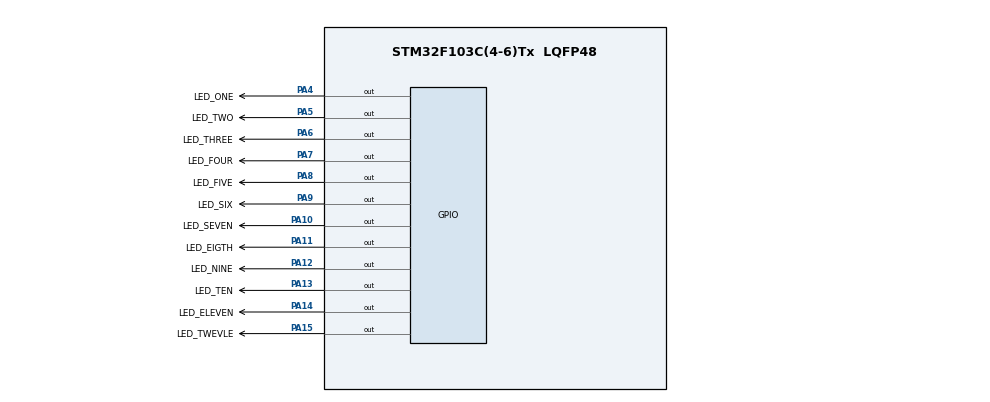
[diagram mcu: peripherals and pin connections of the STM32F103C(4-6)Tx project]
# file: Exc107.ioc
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Mcu.Family=STM32F1
Mcu.Name=STM32F103C(4-6)Tx
Mcu.Package=LQFP48
NVIC.PriorityGroup=NVIC_PRIORITYGROUP_4
PA10.GPIO_Label=LED_SEVEN
PA10.Signal=GPIO_Output
PA11.GPIO_Label=LED_EIGTH
PA11.Signal=GPIO_Output
PA12.GPIO_Label=LED_NINE
PA12.Signal=GPIO_Output
PA13.GPIO_Label=LED_TEN
PA13.Signal=GPIO_Output
PA14.GPIO_Label=LED_ELEVEN
PA14.Signal=GPIO_Output
PA15.GPIO_Label=LED_TWEVLE
PA15.Signal=GPIO_Output
PA4.GPIO_Label=LED_ONE
PA4.Signal=GPIO_Output
PA5.GPIO_Label=LED_TWO
PA5.Signal=GPIO_Output
PA6.GPIO_Label=LED_THREE
PA6.Signal=GPIO_Output
PA7.GPIO_Label=LED_FOUR
PA7.Signal=GPIO_Output
PA8.GPIO_Label=LED_FIVE
PA8.Signal=GPIO_Output
PA9.GPIO_Label=LED_SIX
PA9.Signal=GPIO_Output
ProjectManager.HeapSize=0x200
ProjectManager.StackSize=0x400
ProjectManager.TargetToolchain=STM32CubeIDE
RCC.APB1Freq_Value=8000000
RCC.APB2Freq_Value=8000000
board=custom

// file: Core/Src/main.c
/* USER CODE BEGIN Header */
/**
  ******************************************************************************
  * @file           : main.c
  * @brief          : Main program body
  ******************************************************************************
  * @attention
  *
  * Copyright (c) 2022 STMicroelectronics.
  * All rights reserved.
  *
  * This software is licensed under terms that can be found in the LICENSE file
  * in the root directory of this software component.
  * If no LICENSE file comes with this software, it is provided AS-IS.
  *
  ******************************************************************************
  */
/* USER CODE END Header */
#include "main.h"

void SystemClock_Config(void);
static void MX_GPIO_Init(void);

void clearAllClock(){
	//TODO
	HAL_GPIO_WritePin(LED_ONE_GPIO_Port, LED_ONE_Pin, SET);
	HAL_GPIO_WritePin(LED_TWO_GPIO_Port, LED_TWO_Pin, SET);
	HAL_GPIO_WritePin(LED_THREE_GPIO_Port, LED_THREE_Pin, SET);
	HAL_GPIO_WritePin(LED_FOUR_GPIO_Port, LED_FOUR_Pin, SET);
	HAL_GPIO_WritePin(LED_FIVE_GPIO_Port, LED_FIVE_Pin, SET);
	HAL_GPIO_WritePin(LED_SIX_GPIO_Port, LED_SIX_Pin, SET);
	HAL_GPIO_WritePin(LED_SEVEN_GPIO_Port, LED_SEVEN_Pin, SET);
	HAL_GPIO_WritePin(LED_EIGTH_GPIO_Port, LED_EIGTH_Pin, SET);
	HAL_GPIO_WritePin(LED_NINE_GPIO_Port, LED_NINE_Pin, SET);
	HAL_GPIO_WritePin(LED_TEN_GPIO_Port, LED_TEN_Pin, SET);
	HAL_GPIO_WritePin(LED_ELEVEN_GPIO_Port, LED_ELEVEN_Pin, SET);
	HAL_GPIO_WritePin(LED_TWEVLE_GPIO_Port, LED_TWEVLE_Pin, SET);
}

int main(void)
{

  /* MCU Configuration--------------------------------------------------------*/

  /* Reset of all peripherals, Initializes the Flash interface and the Systick. */
  HAL_Init();

  /* Configure the system clock */
  SystemClock_Config();

  /* Initialize all configured peripherals */
  MX_GPIO_Init();

  /* Infinite loop */
  /* USER CODE BEGIN WHILE */
  int counter  = 0;
  	while (1)
  	{
      /* USER CODE END WHILE */
  		if (counter > 12) {
  			counter = 0;
  			clearAllClock();
  		}
  				switch (counter) {
  				case 1:
  					HAL_GPIO_WritePin(LED_ONE_GPIO_Port, LED_ONE_Pin, RESET);
  					HAL_GPIO_WritePin(LED_TWO_GPIO_Port, LED_TWO_Pin, SET);
  					HAL_GPIO_WritePin(LED_THREE_GPIO_Port, LED_THREE_Pin, SET);
  					HAL_GPIO_WritePin(LED_FOUR_GPIO_Port, LED_FOUR_Pin, SET);
  					HAL_GPIO_WritePin(LED_FIVE_GPIO_Port, LED_FIVE_Pin, SET);
  					HAL_GPIO_WritePin(LED_SIX_GPIO_Port, LED_SIX_Pin, SET);
  					HAL_GPIO_WritePin(LED_SEVEN_GPIO_Port, LED_SEVEN_Pin, SET);
  					HAL_GPIO_WritePin(LED_EIGTH_GPIO_Port, LED_EIGTH_Pin, SET);
  					HAL_GPIO_WritePin(LED_NINE_GPIO_Port, LED_NINE_Pin, SET);
  					HAL_GPIO_WritePin(LED_TEN_GPIO_Port, LED_TEN_Pin, SET);
  					HAL_GPIO_WritePin(LED_ELEVEN_GPIO_Port, LED_ELEVEN_Pin, SET);
  					HAL_GPIO_WritePin(LED_TWEVLE_GPIO_Port, LED_TWEVLE_Pin, SET);
  					break;
  				case 2:
  					HAL_GPIO_WritePin(LED_ONE_GPIO_Port, LED_ONE_Pin, SET);
  					HAL_GPIO_WritePin(LED_TWO_GPIO_Port, LED_TWO_Pin, RESET);
  					HAL_GPIO_WritePin(LED_THREE_GPIO_Port, LED_THREE_Pin, SET);
  					HAL_GPIO_WritePin(LED_FOUR_GPIO_Port, LED_FOUR_Pin, SET);
  					HAL_GPIO_WritePin(LED_FIVE_GPIO_Port, LED_FIVE_Pin, SET);
  					HAL_GPIO_WritePin(LED_SIX_GPIO_Port, LED_SIX_Pin, SET);
  					HAL_GPIO_WritePin(LED_SEVEN_GPIO_Port, LED_SEVEN_Pin, SET);
  					HAL_GPIO_WritePin(LED_EIGTH_GPIO_Port, LED_EIGTH_Pin, SET);
  					HAL_GPIO_WritePin(LED_NINE_GPIO_Port, LED_NINE_Pin, SET);
  					HAL_GPIO_WritePin(LED_TEN_GPIO_Port, LED_TEN_Pin, SET);
  					HAL_GPIO_WritePin(LED_ELEVEN_GPIO_Port, LED_ELEVEN_Pin, SET);
  					HAL_GPIO_WritePin(LED_TWEVLE_GPIO_Port, LED_TWEVLE_Pin, SET);
  					break;
  				case 3:
  					HAL_GPIO_WritePin(LED_ONE_GPIO_Port, LED_ONE_Pin, SET);
  					HAL_GPIO_WritePin(LED_TWO_GPIO_Port, LED_TWO_Pin, SET);
  					HAL_GPIO_WritePin(LED_THREE_GPIO_Port, LED_THREE_Pin, RESET);
  					HAL_GPIO_WritePin(LED_FOUR_GPIO_Port, LED_FOUR_Pin, SET);
  					HAL_GPIO_WritePin(LED_FIVE_GPIO_Port, LED_FIVE_Pin, SET);
  					HAL_GPIO_WritePin(LED_SIX_GPIO_Port, LED_SIX_Pin, SET);
  					HAL_GPIO_WritePin(LED_SEVEN_GPIO_Port, LED_SEVEN_Pin, SET);
  					HAL_GPIO_WritePin(LED_EIGTH_GPIO_Port, LED_EIGTH_Pin, SET);
  					HAL_GPIO_WritePin(LED_NINE_GPIO_Port, LED_NINE_Pin, SET);
  					HAL_GPIO_WritePin(LED_TEN_GPIO_Port, LED_TEN_Pin, SET);
  					HAL_GPIO_WritePin(LED_ELEVEN_GPIO_Port, LED_ELEVEN_Pin, SET);
  					HAL_GPIO_WritePin(LED_TWEVLE_GPIO_Port, LED_TWEVLE_Pin, SET);
  					break;
  				case 4:
  							HAL_GPIO_WritePin(LED_ONE_GPIO_Port, LED_ONE_Pin, SET);
  							HAL_GPIO_WritePin(LED_TWO_GPIO_Port, LED_TWO_Pin, SET);
  							HAL_GPIO_WritePin(LED_THREE_GPIO_Port, LED_THREE_Pin, SET);
  							HAL_GPIO_WritePin(LED_FOUR_GPIO_Port, LED_FOUR_Pin, RESET);
  							HAL_GPIO_WritePin(LED_FIVE_GPIO_Port, LED_FIVE_Pin, SET);
  							HAL_GPIO_WritePin(LED_SIX_GPIO_Port, LED_SIX_Pin, SET);
  							HAL_GPIO_WritePin(LED_SEVEN_GPIO_Port, LED_SEVEN_Pin, SET);
  							HAL_GPIO_WritePin(LED_EIGTH_GPIO_Port, LED_EIGTH_Pin, SET);
  							HAL_GPIO_WritePin(LED_NINE_GPIO_Port, LED_NINE_Pin, SET);
  							HAL_GPIO_WritePin(LED_TEN_GPIO_Port, LED_TEN_Pin, SET);
  							HAL_GPIO_WritePin(LED_ELEVEN_GPIO_Port, LED_ELEVEN_Pin, SET);
  							HAL_GPIO_WritePin(LED_TWEVLE_GPIO_Port, LED_TWEVLE_Pin, SET);
  							break;
  				case 5:
  							HAL_GPIO_WritePin(LED_ONE_GPIO_Port, LED_ONE_Pin, SET);
  							HAL_GPIO_WritePin(LED_TWO_GPIO_Port, LED_TWO_Pin, SET);
  							HAL_GPIO_WritePin(LED_THREE_GPIO_Port, LED_THREE_Pin, SET);
  							HAL_GPIO_WritePin(LED_FOUR_GPIO_Port, LED_FOUR_Pin, SET);
  							HAL_GPIO_WritePin(LED_FIVE_GPIO_Port, LED_FIVE_Pin, RESET);
  							HAL_GPIO_WritePin(LED_SIX_GPIO_Port, LED_SIX_Pin, SET);
  							HAL_GPIO_WritePin(LED_SEVEN_GPIO_Port, LED_SEVEN_Pin, SET);
  							HAL_GPIO_WritePin(LED_EIGTH_GPIO_Port, LED_EIGTH_Pin, SET);
  							HAL_GPIO_WritePin(LED_NINE_GPIO_Port, LED_NINE_Pin, SET);
  							HAL_GPIO_WritePin(LED_TEN_GPIO_Port, LED_TEN_Pin, SET);
  							HAL_GPIO_WritePin(LED_ELEVEN_GPIO_Port, LED_ELEVEN_Pin, SET);
  							HAL_GPIO_WritePin(LED_TWEVLE_GPIO_Port, LED_TWEVLE_Pin, SET);
  							break;
  				case 6:
  							HAL_GPIO_WritePin(LED_ONE_GPIO_Port, LED_ONE_Pin, SET);
  							HAL_GPIO_WritePin(LED_TWO_GPIO_Port, LED_TWO_Pin, SET);
  							HAL_GPIO_WritePin(LED_THREE_GPIO_Port, LED_THREE_Pin, SET);
  							HAL_GPIO_WritePin(LED_FOUR_GPIO_Port, LED_FOUR_Pin, SET);
  							HAL_GPIO_WritePin(LED_FIVE_GPIO_Port, LED_FIVE_Pin, SET);
  							HAL_GPIO_WritePin(LED_SIX_GPIO_Port, LED_SIX_Pin, RESET);
  							HAL_GPIO_WritePin(LED_SEVEN_GPIO_Port, LED_SEVEN_Pin, SET);
  							HAL_GPIO_WritePin(LED_EIGTH_GPIO_Port, LED_EIGTH_Pin, SET);
  							HAL_GPIO_WritePin(LED_NINE_GPIO_Port, LED_NINE_Pin, SET);
  							HAL_GPIO_WritePin(LED_TEN_GPIO_Port, LED_TEN_Pin, SET);
  							HAL_GPIO_WritePin(LED_ELEVEN_GPIO_Port, LED_ELEVEN_Pin, SET);
  							HAL_GPIO_WritePin(LED_TWEVLE_GPIO_Port, LED_TWEVLE_Pin, SET);
  							break;
  				case 7:
  							HAL_GPIO_WritePin(LED_ONE_GPIO_Port, LED_ONE_Pin, SET);
  							HAL_GPIO_WritePin(LED_TWO_GPIO_Port, LED_TWO_Pin, SET);
  							HAL_GPIO_WritePin(LED_THREE_GPIO_Port, LED_THREE_Pin, SET);
  							HAL_GPIO_WritePin(LED_FOUR_GPIO_Port, LED_FOUR_Pin, SET);
  							HAL_GPIO_WritePin(LED_FIVE_GPIO_Port, LED_FIVE_Pin, SET);
  							HAL_GPIO_WritePin(LED_SIX_GPIO_Port, LED_SIX_Pin, SET);
  							HAL_GPIO_WritePin(LED_SEVEN_GPIO_Port, LED_SEVEN_Pin, RESET);
  							HAL_GPIO_WritePin(LED_EIGTH_GPIO_Port, LED_EIGTH_Pin, SET);
  							HAL_GPIO_WritePin(LED_NINE_GPIO_Port, LED_NINE_Pin, SET);
  							HAL_GPIO_WritePin(LED_TEN_GPIO_Port, LED_TEN_Pin, SET);
  							HAL_GPIO_WritePin(LED_ELEVEN_GPIO_Port, LED_ELEVEN_Pin, SET);
  							HAL_GPIO_WritePin(LED_TWEVLE_GPIO_Port, LED_TWEVLE_Pin, SET);
  							break;
  				case 8:
  							HAL_GPIO_WritePin(LED_ONE_GPIO_Port, LED_ONE_Pin, SET);
  							HAL_GPIO_WritePin(LED_TWO_GPIO_Port, LED_TWO_Pin, SET);
  							HAL_GPIO_WritePin(LED_THREE_GPIO_Port, LED_THREE_Pin, SET);
  							HAL_GPIO_WritePin(LED_FOUR_GPIO_Port, LED_FOUR_Pin, SET);
  							HAL_GPIO_WritePin(LED_FIVE_GPIO_Port, LED_FIVE_Pin, SET);
  							HAL_GPIO_WritePin(LED_SIX_GPIO_Port, LED_SIX_Pin, SET);
  							HAL_GPIO_WritePin(LED_SEVEN_GPIO_Port, LED_SEVEN_Pin, SET);
  							HAL_GPIO_WritePin(LED_EIGTH_GPIO_Port, LED_EIGTH_Pin, RESET);
  							HAL_GPIO_WritePin(LED_NINE_GPIO_Port, LED_NINE_Pin, SET);
  							HAL_GPIO_WritePin(LED_TEN_GPIO_Port, LED_TEN_Pin, SET);
  							HAL_GPIO_WritePin(LED_ELEVEN_GPIO_Port, LED_ELEVEN_Pin, SET);
  							HAL_GPIO_WritePin(LED_TWEVLE_GPIO_Port, LED_TWEVLE_Pin, SET);
  							break;
  				case 9:
  							HAL_GPIO_WritePin(LED_ONE_GPIO_Port, LED_ONE_Pin, SET);
  							HAL_GPIO_WritePin(LED_TWO_GPIO_Port, LED_TWO_Pin, SET);
  							HAL_GPIO_WritePin(LED_THREE_GPIO_Port, LED_THREE_Pin, SET);
  							HAL_GPIO_WritePin(LED_FOUR_GPIO_Port, LED_FOUR_Pin, SET);
  							HAL_GPIO_WritePin(LED_FIVE_GPIO_Port, LED_FIVE_Pin, SET);
  							HAL_GPIO_WritePin(LED_SIX_GPIO_Port, LED_SIX_Pin, SET);
  							HAL_GPIO_WritePin(LED_SEVEN_GPIO_Port, LED_SEVEN_Pin, SET);
  							HAL_GPIO_WritePin(LED_EIGTH_GPIO_Port, LED_EIGTH_Pin, SET);
  							HAL_GPIO_WritePin(LED_NINE_GPIO_Port, LED_NINE_Pin, RESET);
  							HAL_GPIO_WritePin(LED_TEN_GPIO_Port, LED_TEN_Pin, SET);
  							HAL_GPIO_WritePin(LED_ELEVEN_GPIO_Port, LED_ELEVEN_Pin, SET);
  							HAL_GPIO_WritePin(LED_TWEVLE_GPIO_Port, LED_TWEVLE_Pin, SET);
  							break;
  				case 10:
  							HAL_GPIO_WritePin(LED_ONE_GPIO_Port, LED_ONE_Pin, SET);
  							HAL_GPIO_WritePin(LED_TWO_GPIO_Port, LED_TWO_Pin, SET);
  							HAL_GPIO_WritePin(LED_THREE_GPIO_Port, LED_THREE_Pin, SET);
  							HAL_GPIO_WritePin(LED_FOUR_GPIO_Port, LED_FOUR_Pin, SET);
  							HAL_GPIO_WritePin(LED_FIVE_GPIO_Port, LED_FIVE_Pin, SET);
  							HAL_GPIO_WritePin(LED_SIX_GPIO_Port, LED_SIX_Pin, SET);
  							HAL_GPIO_WritePin(LED_SEVEN_GPIO_Port, LED_SEVEN_Pin, SET);
  							HAL_GPIO_WritePin(LED_EIGTH_GPIO_Port, LED_EIGTH_Pin, SET);
  							HAL_GPIO_WritePin(LED_NINE_GPIO_Port, LED_NINE_Pin, SET);
  							HAL_GPIO_WritePin(LED_TEN_GPIO_Port, LED_TEN_Pin, RESET);
  							HAL_GPIO_WritePin(LED_ELEVEN_GPIO_Port, LED_ELEVEN_Pin, SET);
  							HAL_GPIO_WritePin(LED_TWEVLE_GPIO_Port, LED_TWEVLE_Pin, SET);
  							break;
  				case 11:
  							HAL_GPIO_WritePin(LED_ONE_GPIO_Port, LED_ONE_Pin, SET);
  							HAL_GPIO_WritePin(LED_TWO_GPIO_Port, LED_TWO_Pin, SET);
  							HAL_GPIO_WritePin(LED_THREE_GPIO_Port, LED_THREE_Pin, SET);
  							HAL_GPIO_WritePin(LED_FOUR_GPIO_Port, LED_FOUR_Pin, SET);
  							HAL_GPIO_WritePin(LED_FIVE_GPIO_Port, LED_FIVE_Pin, SET);
  							HAL_GPIO_WritePin(LED_SIX_GPIO_Port, LED_SIX_Pin, SET);
  							HAL_GPIO_WritePin(LED_SEVEN_GPIO_Port, LED_SEVEN_Pin, SET);
  							HAL_GPIO_WritePin(LED_EIGTH_GPIO_Port, LED_EIGTH_Pin, SET);
  							HAL_GPIO_WritePin(LED_NINE_GPIO_Port, LED_NINE_Pin, SET);
  							HAL_GPIO_WritePin(LED_TEN_GPIO_Port, LED_TEN_Pin, SET);
  							HAL_GPIO_WritePin(LED_ELEVEN_GPIO_Port, LED_ELEVEN_Pin, RESET);
  							HAL_GPIO_WritePin(LED_TWEVLE_GPIO_Port, LED_TWEVLE_Pin, SET);
  							break;
  				case 12:
  							HAL_GPIO_WritePin(LED_ONE_GPIO_Port, LED_ONE_Pin, SET);
  							HAL_GPIO_WritePin(LED_TWO_GPIO_Port, LED_TWO_Pin, SET);
  							HAL_GPIO_WritePin(LED_THREE_GPIO_Port, LED_THREE_Pin, SET);
  							HAL_GPIO_WritePin(LED_FOUR_GPIO_Port, LED_FOUR_Pin, SET);
  							HAL_GPIO_WritePin(LED_FIVE_GPIO_Port, LED_FIVE_Pin, SET);
  							HAL_GPIO_WritePin(LED_SIX_GPIO_Port, LED_SIX_Pin, SET);
  							HAL_GPIO_WritePin(LED_SEVEN_GPIO_Port, LED_SEVEN_Pin, SET);
  							HAL_GPIO_WritePin(LED_EIGTH_GPIO_Port, LED_EIGTH_Pin, SET);
  							HAL_GPIO_WritePin(LED_NINE_GPIO_Port, LED_NINE_Pin, SET);
  							HAL_GPIO_WritePin(LED_TEN_GPIO_Port, LED_TEN_Pin, SET);
  							HAL_GPIO_WritePin(LED_ELEVEN_GPIO_Port, LED_ELEVEN_Pin, SET);
  							HAL_GPIO_WritePin(LED_TWEVLE_GPIO_Port, LED_TWEVLE_Pin, RESET);
  							break;
  				default:
  					break;
  				}
  				counter++;
  				HAL_Delay(1000);
  	}
}

void SystemClock_Config(void)
{
  RCC_OscInitTypeDef RCC_OscInitStruct = {0};
  RCC_ClkInitTypeDef RCC_ClkInitStruct = {0};

  /** Initializes the RCC Oscillators according to the specified parameters
  * in the RCC_OscInitTypeDef structure.
  */
  RCC_OscInitStruct.OscillatorType = RCC_OSCILLATORTYPE_HSI;
  RCC_OscInitStruct.HSIState = RCC_HSI_ON;
  RCC_OscInitStruct.HSICalibrationValue = RCC_HSICALIBRATION_DEFAULT;
  RCC_OscInitStruct.PLL.PLLState = RCC_PLL_NONE;
  if (HAL_RCC_OscConfig(&RCC_OscInitStruct) != HAL_OK)
  {
    Error_Handler();
  }

  /** Initializes the CPU, AHB and APB buses clocks
  */
  RCC_ClkInitStruct.ClockType = RCC_CLOCKTYPE_HCLK|RCC_CLOCKTYPE_SYSCLK
                              |RCC_CLOCKTYPE_PCLK1|RCC_CLOCKTYPE_PCLK2;
  RCC_ClkInitStruct.SYSCLKSource = RCC_SYSCLKSOURCE_HSI;
  RCC_ClkInitStruct.AHBCLKDivider = RCC_SYSCLK_DIV1;
  RCC_ClkInitStruct.APB1CLKDivider = RCC_HCLK_DIV1;
  RCC_ClkInitStruct.APB2CLKDivider = RCC_HCLK_DIV1;

  if (HAL_RCC_ClockConfig(&RCC_ClkInitStruct, FLASH_LATENCY_0) != HAL_OK)
  {
    Error_Handler();
  }
}

static void MX_GPIO_Init(void)
{
  GPIO_InitTypeDef GPIO_InitStruct = {0};

  /* GPIO Ports Clock Enable */
  __HAL_RCC_GPIOA_CLK_ENABLE();

  /*Configure GPIO pin Output Level */
  HAL_GPIO_WritePin(GPIOA, LED_ONE_Pin|LED_TWO_Pin|LED_THREE_Pin|LED_FOUR_Pin
                          |LED_FIVE_Pin|LED_SIX_Pin|LED_SEVEN_Pin|LED_EIGTH_Pin
                          |LED_NINE_Pin|LED_TEN_Pin|LED_ELEVEN_Pin|LED_TWEVLE_Pin, GPIO_PIN_RESET);

  /*Configure GPIO pins : LED_ONE_Pin LED_TWO_Pin LED_THREE_Pin LED_FOUR_Pin
                           LED_FIVE_Pin LED_SIX_Pin LED_SEVEN_Pin LED_EIGTH_Pin
                           LED_NINE_Pin LED_TEN_Pin LED_ELEVEN_Pin LED_TWEVLE_Pin */
  GPIO_InitStruct.Pin = LED_ONE_Pin|LED_TWO_Pin|LED_THREE_Pin|LED_FOUR_Pin
                          |LED_FIVE_Pin|LED_SIX_Pin|LED_SEVEN_Pin|LED_EIGTH_Pin
                          |LED_NINE_Pin|LED_TEN_Pin|LED_ELEVEN_Pin|LED_TWEVLE_Pin;
  GPIO_InitStruct.Mode = GPIO_MODE_OUTPUT_PP;
  GPIO_InitStruct.Pull = GPIO_NOPULL;
  GPIO_InitStruct.Speed = GPIO_SPEED_FREQ_LOW;
  HAL_GPIO_Init(GPIOA, &GPIO_InitStruct);

}

void Error_Handler(void)
{
  __disable_irq();
  while (1)
  {
  }
}
